AUTOSAR XML (schema 00046)
package /VehicleProject
  system System
    system mapping System_MPPNG
      data-mappings:
        sender-receiver-to-signal-group-mapping={data-element=SG_Sig_Grp_0x110.SG_Sig_Grp_0x110, signal-group=SG_Sig_Grp_0x110, type-mapping=sender-rec-record-type-mapping=record-element-mappings=[{implementation-record-element=Led1_State, system-signal=Led1_State}, {implementation-record-element=Led2_State, system-signal=Led2_State}, {implementation-record-element=Led3_State, system-signal=Led3_State}, {implementation-record-element=Led4_State, system-signal=Led4_State}]}
        sender-receiver-to-signal-group-mapping={data-element=SG_Sig_Grp_0x111.SG_Sig_Grp_0x111, signal-group=SG_Sig_Grp_0x111, type-mapping=sender-rec-record-type-mapping=record-element-mappings=[{implementation-record-element=Button1_State, system-signal=Button1_State}, {implementation-record-element=Button2_State, system-signal=Button2_State}, {implementation-record-element=Button3_State, system-signal=Button3_State}, {implementation-record-element=Button4_State, system-signal=Button4_State}]}
        sender-receiver-to-signal-group-mapping={data-element=SG_Sig_Grp_0x112.SG_Sig_Grp_0x112, signal-group=SG_Sig_Grp_0x112, type-mapping=sender-rec-record-type-mapping=record-element-mappings=[{implementation-record-element=PowerMode, system-signal=PowerMode}, {implementation-record-element=SupA_Checksum_0x112, system-signal=SupA_Checksum_0x112}, {implementation-record-element=SupA_Counter_0x112, system-signal=SupA_Counter_0x112}]}
        sender-receiver-to-signal-group-mapping={data-element=SG_Sig_Grp_0x113.SG_Sig_Grp_0x113, signal-group=SG_Sig_Grp_0x113, type-mapping=sender-rec-record-type-mapping=sender-rec-record-element-mapping{implementation-record-element=AAA_Angle, system-signal=AAA_Angle}}
        sender-receiver-to-signal-group-mapping={data-element=SG_Sig_Grp_0x400.SG_Sig_Grp_0x400, signal-group=SG_Sig_Grp_0x400, type-mapping=sender-rec-record-type-mapping=record-element-mappings=[{implementation-record-element=CrcSig_Pack_0, system-signal=CrcSig_Pack_0}, {implementation-record-element=CrcSig_Pack_1, system-signal=CrcSig_Pack_1}, {implementation-record-element=CrcSig_Pack_2, system-signal=CrcSig_Pack_2}, {implementation-record-element=Led1_Control, system-signal=Led1_Control}, {implementation-record-element=Led2_Control, system-signal=Led2_Control}, {implementation-record-element=Led3_Control, system-signal=Led3_Control}, {implementation-record-element=Led4_Control, system-signal=Led4_Control}, {implementation-record-element=SupB_Checksum_0x400, system-signal=SupB_Checksum_0x400}, {implementation-record-element=SupB_Counter_0x400, system-signal=SupB_Counter_0x400}]}
        sender-receiver-to-signal-group-mapping={data-element=SG_Sig_Grp_0x401.SG_Sig_Grp_0x401, signal-group=SG_Sig_Grp_0x401, type-mapping=sender-rec-record-type-mapping=record-element-mappings=[{implementation-record-element=Button1_Control, system-signal=Button1_Control}, {implementation-record-element=Button2_Control, system-signal=Button2_Control}, {implementation-record-element=Button3_Control, system-signal=Button3_Control}, {implementation-record-element=Button4_Control, system-signal=Button4_Control}]}
        sender-receiver-to-signal-group-mapping={data-element=SG_Sig_Grp_0x402.SG_Sig_Grp_0x402, signal-group=SG_Sig_Grp_0x402, type-mapping=sender-rec-record-type-mapping=record-element-mappings=[{implementation-record-element=Sig_0x402_Used_1, system-signal=Sig_0x402_Used_1}, {implementation-record-element=Sig_0x402_Used_2, system-signal=Sig_0x402_Used_2}, {implementation-record-element=Sig_0x402_Used_3, system-signal=Sig_0x402_Used_3}, {implementation-record-element=Sig_0x402_Used_4, system-signal=Sig_0x402_Used_4}, {implementation-record-element=Sig_0x402_Used_5, system-signal=Sig_0x402_Used_5}]}
        sender-receiver-to-signal-group-mapping={data-element=SG_Sig_Grp_0x403.SG_Sig_Grp_0x403, signal-group=SG_Sig_Grp_0x403, type-mapping=sender-rec-record-type-mapping=record-element-mappings=[{implementation-record-element=Sig_0x403_Used_1, system-signal=Sig_0x403_Used_1}, {implementation-record-element=Sig_0x403_Used_2, system-signal=Sig_0x403_Used_2}, {implementation-record-element=Sig_0x403_Used_3, system-signal=Sig_0x403_Used_3}, {implementation-record-element=Sig_0x403_Used_4, system-signal=Sig_0x403_Used_4}, {implementation-record-element=Sig_0x403_Used_5, system-signal=Sig_0x403_Used_5}]}
        sender-receiver-to-signal-mapping={data-element=Sig_0x114_Used_6.Sig_0x114_Used_6, system-signal=Sig_0x114_Used_6}
        sender-receiver-to-signal-group-mapping={data-element=SG_Sig_Grp_0x114.SG_Sig_Grp_0x114, signal-group=SG_Sig_Grp_0x114, type-mapping=sender-rec-record-type-mapping=record-element-mappings=[{implementation-record-element=Sig_0x114_Used_1, system-signal=Sig_0x114_Used_1}, {implementation-record-element=Sig_0x114_Used_2, system-signal=Sig_0x114_Used_2}, {implementation-record-element=Sig_0x114_Used_3, system-signal=Sig_0x114_Used_3}, {implementation-record-element=Sig_0x114_Used_4, system-signal=Sig_0x114_Used_4}, {implementation-record-element=Sig_0x114_Used_5, system-signal=Sig_0x114_Used_5}]}
    root-software-compositions:
      root sw composition prototype EcuSwComposition: software-composition=ECU_Composition
package /ECUCompositionTypes
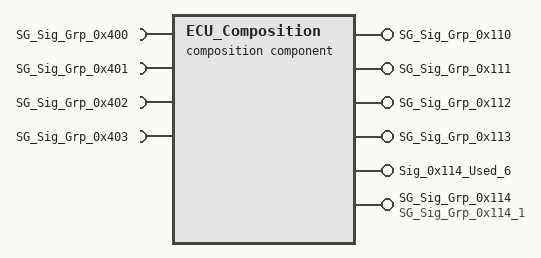
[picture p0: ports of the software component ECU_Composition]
  composition sw component type ECU_Composition
    4 x provide port:
      SG_Sig_Grp_0x110: nonqueued-sender-com-spec{data-element=SG_Sig_Grp_0x110, init-value=fields=[Led1_State:0, Led2_State:0, Led3_State:0, Led4_State:0]}, provided-interface=SG_Sig_Grp_0x110
      SG_Sig_Grp_0x111: nonqueued-sender-com-spec{data-element=SG_Sig_Grp_0x111, init-value=fields=[Button1_State:0, Button2_State:0, Button3_State:0, Button4_State:0]}, provided-interface=SG_Sig_Grp_0x111
      SG_Sig_Grp_0x112: nonqueued-sender-com-spec{data-element=SG_Sig_Grp_0x112, uses-end-to-end-protection=true, init-value=fields=[PowerMode:0, SupA_Checksum_0x112:0, SupA_Counter_0x112:0]}, provided-interface=SG_Sig_Grp_0x112
      SG_Sig_Grp_0x113: nonqueued-sender-com-spec{data-element=SG_Sig_Grp_0x113, init-value=fields=System_Run_Time:20}, provided-interface=SG_Sig_Grp_0x113
    4 x require port:
      SG_Sig_Grp_0x400: nonqueued-receiver-com-spec{data-element=SG_Sig_Grp_0x400, end-to-end-transformation-com-spec-props=disable-end-to-end-check=false, uses-end-to-end-protection=true, enable-update=true, init-value=fields=[CrcSig_Pack_0:0, CrcSig_Pack_1:0, CrcSig_Pack_2:0, Led1_Control:1, Led2_Control:1, Led3_Control:1, Led4_Control:1, SupB_Checksum_0x400:0, SupB_Counter_0x400:0]}, required-interface=SG_Sig_Grp_0x400
      SG_Sig_Grp_0x401: nonqueued-receiver-com-spec{data-element=SG_Sig_Grp_0x401, init-value=fields=[Button1_Control:0, Button2_Control:0, Button3_Control:0, Button4_Control:0]}, required-interface=SG_Sig_Grp_0x401
      SG_Sig_Grp_0x402: nonqueued-receiver-com-spec{data-element=SG_Sig_Grp_0x402, init-value=fields=[Sig_0x402_Used_1:0, Sig_0x402_Used_2:0, Sig_0x402_Used_3:0, Sig_0x402_Used_4:0, Sig_0x402_Used_5:0]}, required-interface=SG_Sig_Grp_0x402
      SG_Sig_Grp_0x403: nonqueued-receiver-com-spec{data-element=SG_Sig_Grp_0x403, init-value=fields=[Sig_0x403_Used_1:0, Sig_0x403_Used_2:0, Sig_0x403_Used_3:0, Sig_0x403_Used_4:0, Sig_0x403_Used_5:0]}, required-interface=SG_Sig_Grp_0x403
    provide port Sig_0x114_Used_6: nonqueued-sender-com-spec{data-element=Sig_0x114_Used_6, init-value=0}, provided-interface=Sig_0x114_Used_6
    provide port SG_Sig_Grp_0x114: nonqueued-sender-com-spec{data-element=SG_Sig_Grp_0x114, init-value=fields=[Sig_0x114_Used_1:0, Sig_0x114_Used_2:0, Sig_0x114_Used_3:0, Sig_0x114_Used_4:0, Sig_0x114_Used_5:0]}, provided-interface=SG_Sig_Grp_0x114_1
    10 x component:
      AppCtrl: type=AppCtrl
      AppComTx: type=AppComTx
      AppComRx: type=AppComRx
      AppWakeUpCtrl: type=AppWakeUpCtrl
      AppButtonCtrl: type=AppButtonCtrl
      AppLedCtrl: type=AppLedCtrl
      IoHwAb: type=IoHwAb
      AppCtrl2: type=AppCtrl2
      AppCtrl1: type=AppCtrl1
      IcuCdd: type=IcuCdd
    delegate AppComRx.SG_Sig_Grp_0x400 <-> outer port SG_Sig_Grp_0x400
    delegate AppComRx.SG_Sig_Grp_0x401 <-> outer port SG_Sig_Grp_0x401
    delegate AppComRx.SG_Sig_Grp_0x403 <-> outer port SG_Sig_Grp_0x403
    delegate AppComRx.SG_Sig_Grp_0x402 <-> outer port SG_Sig_Grp_0x402
    delegate AppComTx.SG_Sig_Grp_0x{110..113} <-> outer port SG_Sig_Grp_0x{110..113}
    connect AppComRx.SG_Sig_Grp_0x{400..403}_SR_S -> AppCtrl.SG_Sig_Grp_0x{400..403}_SR_R
    connect AppCtrl.SG_Sig_Grp_0x112_SR_S -> AppComTx.SG_Sig_Grp_0x112_SR_R
    connect AppCtrl.SG_Sig_Grp_0x113_SR_S -> AppComTx.SG_Sig_Grp_0x113_SR_R
    connect AppComRx.SG_Sig_Grp_0x401_SR_S -> AppButtonCtrl.SG_Sig_Grp_0x401_SR_R
    connect AppComRx.SG_Sig_Grp_0x400_SR_S -> AppLedCtrl.SG_Sig_Grp_0x400_SR_R
    connect AppLedCtrl.SG_Sig_Grp_0x110_SR_S -> AppComTx.SG_Sig_Grp_0x110_SR_R
    connect AppButtonCtrl.SG_Sig_Grp_0x111_SR_S -> AppComTx.SG_Sig_Grp_0x111_SR_R
    connect IoHwAb.IoHwAbCS_LED{1..4} -> AppLedCtrl.IoHwAbCS_LED{1..4}
    connect IoHwAb.IoHwAbCS_KL15 -> AppLedCtrl.IoHwAbCS_KL15
    connect IoHwAb.IoHwAbCS_KL15 -> AppButtonCtrl.IoHwAbCS_KL15
    connect IoHwAb.IoHwAbCS_Button1 -> AppButtonCtrl.IoHwAbCS_Button1
    connect IoHwAb.IoHwAbCS_Button3 -> AppButtonCtrl.IoHwAbCS_Button3
    connect IoHwAb.IoHwAbCS_Button4 -> AppButtonCtrl.IoHwAbCS_Button4
    connect IoHwAb.IoHwAbCS_Button2 -> AppButtonCtrl.IoHwAbCS_Button2
    connect IoHwAb.IoHwAbCS_KL15 -> AppWakeUpCtrl.IoHwAbCS_KL15
    connect IoHwAb.IoHwAbCS_KL15 -> AppCtrl.IoHwAbCS_KL15
    connect IoHwAb.IoHwAbCS_Button1 -> IcuCdd.IoHwAbCS_Button1
    connect AppCtrl.Sig_0x114_Used_SR_S -> AppComTx.Sig_0x114_Used_SR_R
    delegate AppComTx.Sig_0x114_Used_6 <-> outer port Sig_0x114_Used_6
    connect AppCtrl.SG_Sig_Grp_0x114_SR_S -> AppComTx.SG_Sig_Grp_0x114_SR_R
    delegate AppComTx.SG_Sig_Grp_0x114 <-> outer port SG_Sig_Grp_0x114
    connect AppCtrl.Trigger_Msg_State_SR_S -> AppComTx.Trigger_Msg_State_SR_R
package /EndToEndProtections
  end to end protection set EndToEndProtectionSet
    end to end protection ECU_Composition_SG_Sig_Grp_0x400_SG_Sig_Grp_0x400: end-to-end-profile={category=PROFILE_01, data-ids=13124, data-id-mode=0, data-length=64, max-delta-counter-init=2, crc-offset=0, counter-offset=56, max-no-new-or-repeated-data=15, sync-counter-init=1, data-id-nibble-offset=0}, end-to-end-protection-variable-prototype=receiver=EcuSwComposition.SG_Sig_Grp_0x400.SG_Sig_Grp_0x400
    end to end protection ECU_Composition_SG_Sig_Grp_0x112_SG_Sig_Grp_0x112: end-to-end-profile={category=PROFILE_01, data-ids=4386, data-id-mode=0, data-length=64, max-delta-counter-init=2, crc-offset=0, counter-offset=56, max-no-new-or-repeated-data=15, sync-counter-init=1, data-id-nibble-offset=0}, end-to-end-protection-variable-prototype=EcuSwComposition.SG_Sig_Grp_0x112.SG_Sig_Grp_0x112
